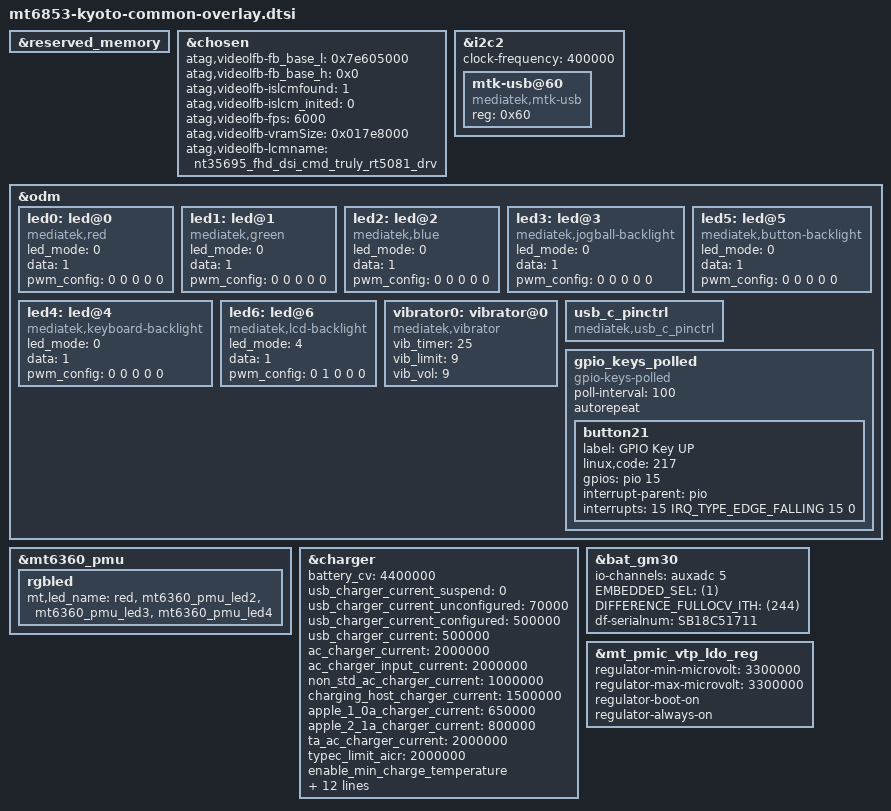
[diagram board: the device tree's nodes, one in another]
/* Copyright (c) 2021, The Linux Foundation. All rights reserved.
 *
 * This program is free software; you can redistribute it and/or modify
 * it under the terms of the GNU General Public License version 2 and
 * only version 2 as published by the Free Software Foundation.
 *
 * This program is distributed in the hope that it will be useful,
 * but WITHOUT ANY WARRANTY; without even the implied warranty of
 * MERCHANTABILITY or FITNESS FOR A PARTICULAR PURPOSE.  See the
 * GNU General Public License for more details.
 */

#include "mediatek/mt6853-moto-common-overlay.dtsi"
#include "mediatek/mt6785-lisbon-audio-overlay.dtsi"
#include "mediatek/mt6785-lisbon-sensor-overlay.dtsi"

&reserved_memory {
};

/* chosen */
&chosen {
	/* fpga may has no lk, we need to specify display info here */
	/* fb buffer is reserved using this dts by memory node above */

	atag,videolfb-fb_base_l = <0x7e605000>;
	atag,videolfb-fb_base_h = <0x0>;
	atag,videolfb-islcmfound = <1>;
	atag,videolfb-islcm_inited = <0>;
	atag,videolfb-fps= <6000>;
	atag,videolfb-vramSize= <0x017e8000>;
	atag,videolfb-lcmname=
		"nt35695_fhd_dsi_cmd_truly_rt5081_drv";
};


&i2c2 {
	clock-frequency = <400000>;

	mtk-usb@60 {
		compatible = "mediatek,mtk-usb";
		reg = <0x60>;
		status = "okay";
	};
};

&odm {
	led0:led@0 {
		compatible = "mediatek,red";
		led_mode = <0>;
		data = <1>;
		pwm_config = <0 0 0 0 0>;
	};
	led1:led@1 {
		compatible = "mediatek,green";
		led_mode = <0>;
		data = <1>;
		pwm_config = <0 0 0 0 0>;
	};
	led2:led@2 {
		compatible = "mediatek,blue";
		led_mode = <0>;
		data = <1>;
		pwm_config = <0 0 0 0 0>;
	};
	led3:led@3 {
		compatible = "mediatek,jogball-backlight";
		led_mode = <0>;
		data = <1>;
		pwm_config = <0 0 0 0 0>;
	};
	led4:led@4 {
		compatible = "mediatek,keyboard-backlight";
		led_mode = <0>;
		data = <1>;
		pwm_config = <0 0 0 0 0>;
	};
	led5:led@5 {
		compatible = "mediatek,button-backlight";
		led_mode = <0>;
		data = <1>;
		pwm_config = <0 0 0 0 0>;
	};
	led6:led@6 {
		compatible = "mediatek,lcd-backlight";
		led_mode = <4>;
		data = <1>;
		pwm_config = <0 1 0 0 0>;
	};
	vibrator0:vibrator@0 {
		compatible = "mediatek,vibrator";
		vib_timer = <25>;
		vib_limit = <9>;
		vib_vol= <9>;
	};

	usb_c_pinctrl:usb_c_pinctrl {
		compatible = "mediatek,usb_c_pinctrl";
	};

	gpio_keys_polled {
		compatible = "gpio-keys-polled";
		poll-interval = <100>;
		autorepeat;

		button21 {
			label = "GPIO Key UP";
			linux,code = <217>;
			gpios = <&pio 15 0>;
			interrupt-parent = <&pio>;
			interrupts = <15 IRQ_TYPE_EDGE_FALLING 15 0>;
			status = "okay";
		};
	};
};

&mt6360_pmu {
	rgbled {
		mt,led_name = "red", "mt6360_pmu_led2",
		"mt6360_pmu_led3", "mt6360_pmu_led4";
	};
};
/*
&moto_chg_tcmd {
                compatible = "mmi,moto-chg-tcmd";
                status = "okay";

                mmi,ntc_table = <1>;
                mmi,ntc_v_ref = <1800000>;
                mmi,ntc_r_pull = <100000>;

                mmi,batid_v_ref = <1800000>;
                mmi,batid_r_pull = <100000>;

                mmi,adc-channel-cpu = <0>;
                mmi,adc-channel-charger = <2>;
                mmi,adc-channel-pa = <1>;
                mmi,adc-channel-batid = <3>;
                mmi,adc-channel-vbat = <100>;
};
*/
&charger {
        /* common */
        battery_cv = <4400000>;

        /* charging current */
        usb_charger_current_suspend = <0>;
        usb_charger_current_unconfigured = <70000>;
        usb_charger_current_configured = <500000>;
        usb_charger_current = <500000>;
        ac_charger_current = <2000000>;
        ac_charger_input_current = <2000000>;
        non_std_ac_charger_current = <1000000>;
        charging_host_charger_current = <1500000>;
        apple_1_0a_charger_current = <650000>;
        apple_2_1a_charger_current = <800000>;
        ta_ac_charger_current = <2000000>;
        typec_limit_aicr = <2000000>;

        /* battery temperature protection */
        enable_min_charge_temperature;
        min_charge_temperature = <0>;
        min_charge_temperature_plus_x_degree = <10>;
        max_charge_temperature = <60>;
        max_charge_temperature_minus_x_degree = <45>;

        /*mmi config*/
        mmi,iterm-ma = <243>;
        mmi,mmi-temp-zones = <0 4200 1000 0>,
                        <10 0 1000 1000>,
                        <15 4200 2500 1000>,
                        <45 0 4000 4000>,
                        <60 4200 3600 0>;
        mmi,enable-charging-limit;
        mmi,upper-limit-capacity = <65>;
        mmi,lower-limit-capacity = <60>;
        mmi,vfloat-comp-uv = <20000>;
};

&bat_gm30 {
        io-channels = <&auxadc 5>;
        io-channel-names = "batteryID-channel";
        EMBEDDED_SEL = <(1)>;   /* embedded battery.*/
        DIFFERENCE_FULLOCV_ITH = <(244)>;       /*Charging termination current.*/

        df-serialnum = "SB18C51711";
        #include "bat_setting/batterytable_kg40_atl_4000mah_ext.dtsi"
};

&mt_pmic_vtp_ldo_reg {
	regulator-min-microvolt = <3300000>;
	regulator-max-microvolt = <3300000>;
	regulator-boot-on;
	regulator-always-on;
};

//#include "mediatek/cust_mt6785_camera.dtsi"
//#include "mediatek/cust_mt6785_touch_1080x2460.dtsi"
//#include "mediatek/mt6785-moto-lisbon-fps.dtsi"
/*End of this file, DO NOT ADD ANYTHING HERE*/
